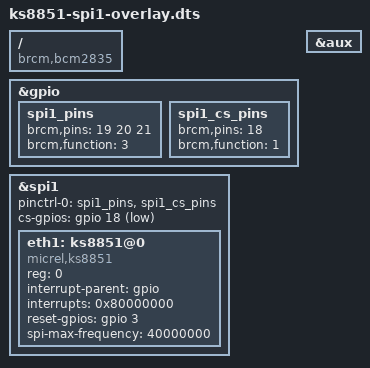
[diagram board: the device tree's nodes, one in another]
// Overlay for the Micrel KS8851 Ethernet mac - SPI1 Compute Module
// Reset pin: 3

/dts-v1/;
/plugin/;

/ {
		compatible = "brcm,bcm2835";

		fragment@0 {
			target = <&gpio>;
			__overlay__ {
				spi1_pins: spi1_pins {
					brcm,pins = <19 20 21>;
					brcm,function = <3>; /* alt4 */
				};
				
				spi1_cs_pins: spi1_cs_pins {
					brcm,pins     = <18>;
					brcm,function = <1>; /* gpio out */
				};
			};
		};

	fragment@1 {
		target = <&aux>;
		__overlay__ {
			status = "okay";
		};
	};
	
		fragment@2 {
			target = <&spi1>;
			__overlay__ {
				/* needed to avoid dtc warning */
				#address-cells = <1>;
				#size-cells = <0>;
				pinctrl-names = "default";
				pinctrl-0 = <&spi1_pins &spi1_cs_pins>;
				cs-gpios = <&gpio 18 1>;
				status = "okay";

				eth1: ks8851@0{
					compatible = "micrel,ks8851";
					reg = <0>; /* CE0 */
					interrupt-parent = <&gpio>;
					interrupts = <0x80000000>; /* not connected */
					reset-gpios = <&gpio 3 0>;
					spi-max-frequency = <40000000>;
					status = "okay";
				};
			};
		};

	__overrides__ {
		speed     = <&eth1>, "spi-max-frequency:0";
	};
};
